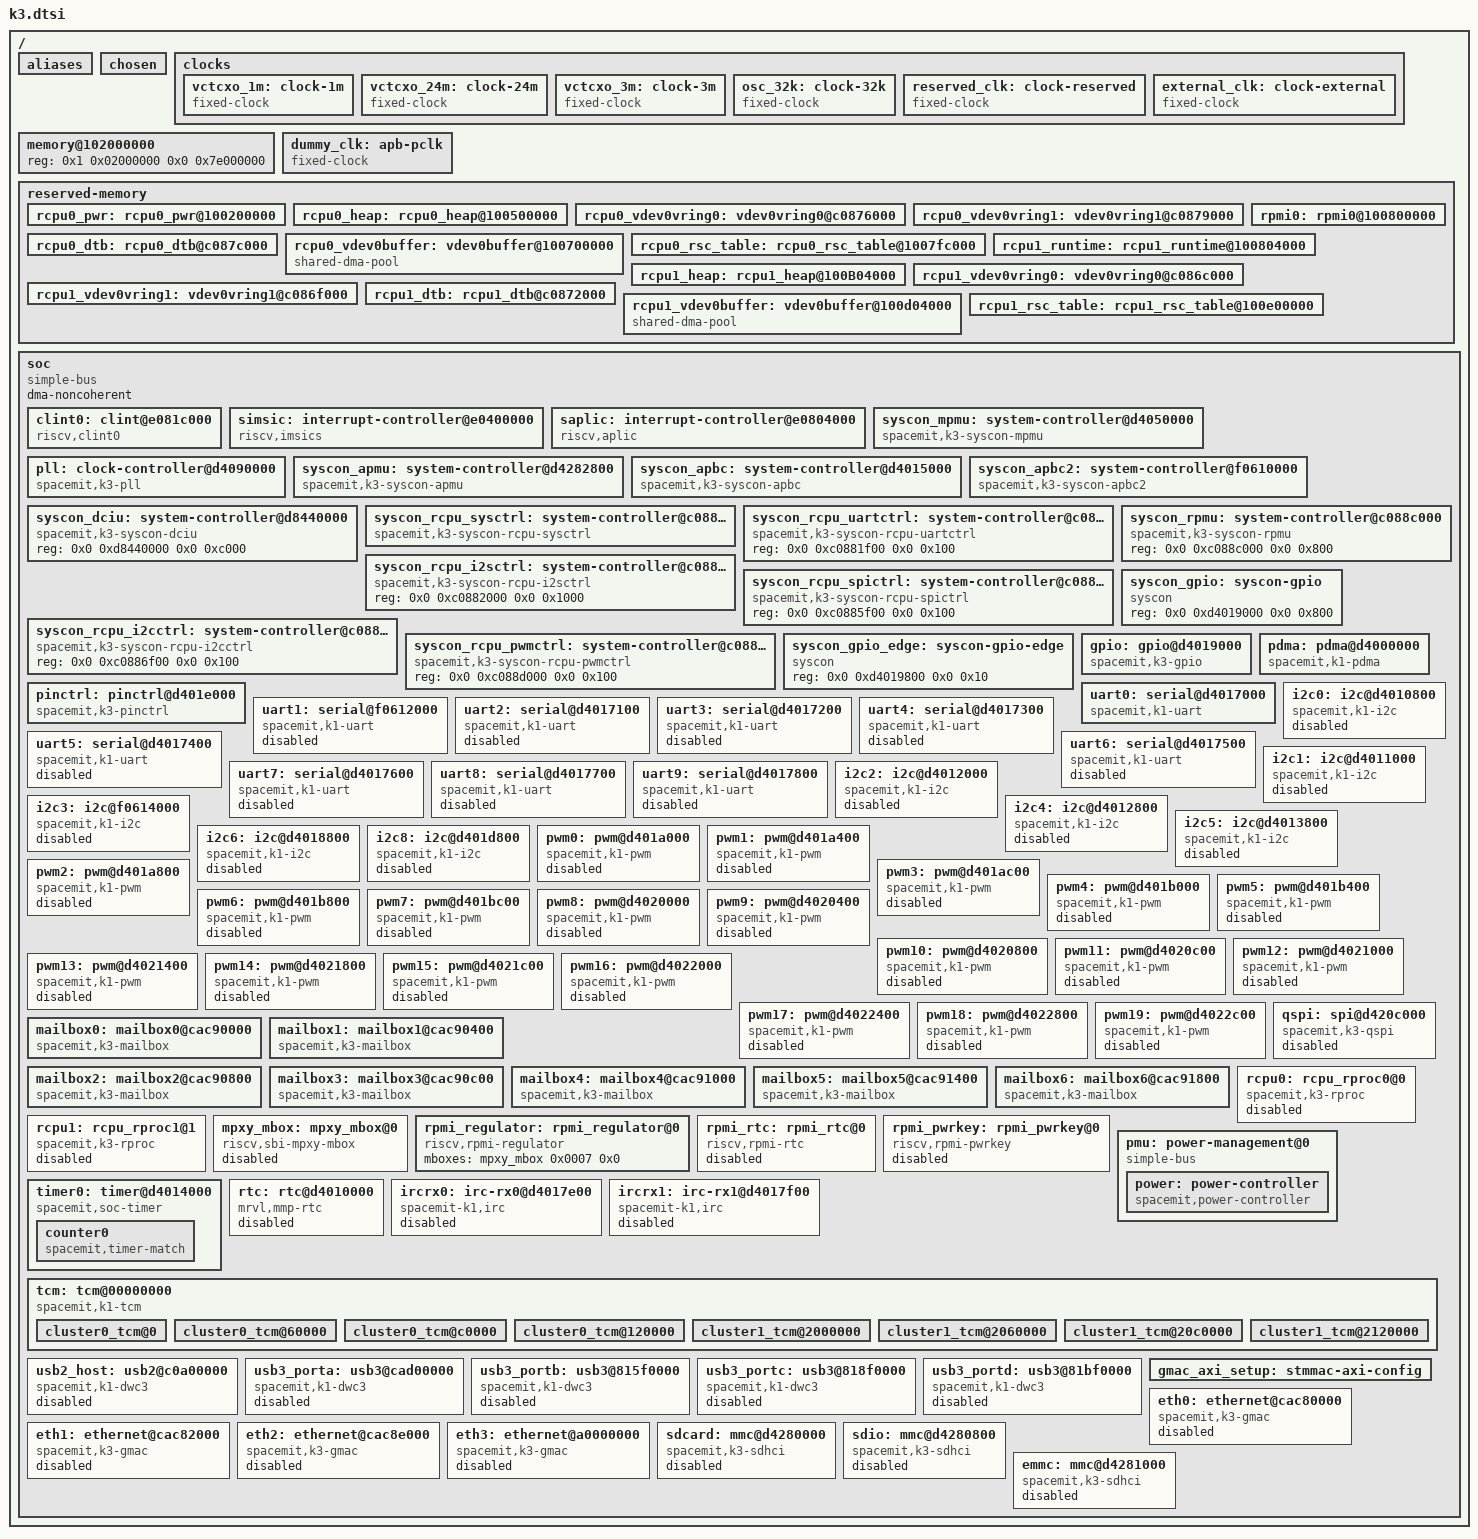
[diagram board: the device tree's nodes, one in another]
// SPDX-License-Identifier: (GPL-2.0 OR MIT)
/* Copyright (c) 2025 Spacemit, Inc */

/dts-v1/;

/* Inline SoC GPIO helper: expand a linear GPIO to <bank,offset> */
#define K3_GPIO(x) ((x) / 32) ((x) % 32)
#include "k3-cpus.dtsi"
#include <dt-bindings/gpio/gpio.h>
#include <dt-bindings/clock/spacemit,k3-syscon.h>
#include <dt-bindings/interrupt-controller/irq.h>

/ {
	#address-cells = <2>;
	#size-cells = <2>;

	aliases {
		serial0 = &uart0;
		serial1 = &uart1;
		serial2 = &uart2;
		serial3 = &uart3;
		serial4 = &uart4;
		serial5 = &uart5;
		serial6 = &uart6;
		serial7 = &uart7;
		serial8 = &uart8;
		serial9 = &uart9;
		serial10 = &r_uart0;
		serial11 = &r_uart1;
		serial12 = &r_uart2;
		serial13 = &r_uart3;
		serial14 = &r_uart4;
		serial15 = &r_uart5;
		mmc0 = &sdcard;
		mmc1 = &sdio;
		mmc2 = &emmc;
		ethernet0 = &eth0;
		ethernet1 = &eth1;
		ethernet2 = &eth2;
		ethernet3 = &eth3;
	};

	chosen {
		bootargs = "earlycon=sbi console=ttyS0,115200 clk_ignore_unused nohlt loglevel=8 initcall_debug=1 memblock=debug";
		stdout-path = "serial0:115200";
	};

	clocks {
		vctcxo_1m: clock-1m {
			compatible = "fixed-clock";
			clock-frequency = <1000000>;
			clock-output-names = "vctcxo_1m";
			#clock-cells = <0>;
		};

		vctcxo_24m: clock-24m {
			compatible = "fixed-clock";
			clock-frequency = <24000000>;
			clock-output-names = "vctcxo_24m";
			#clock-cells = <0>;
		};

		vctcxo_3m: clock-3m {
			compatible = "fixed-clock";
			clock-frequency = <3000000>;
			clock-output-names = "vctcxo_3m";
			#clock-cells = <0>;
		};

		osc_32k: clock-32k {
			compatible = "fixed-clock";
			clock-frequency = <32000>;
			clock-output-names = "osc_32k";
			#clock-cells = <0>;
		};

		reserved_clk: clock-reserved {
			compatible = "fixed-clock";
			clock-frequency = <0>;
			clock-output-names = "reserved_clk";
			#clock-cells = <0>;
		};

		external_clk: clock-external {
			compatible = "fixed-clock";
			clock-frequency = <0>;
			clock-output-names = "external_clk";
			#clock-cells = <0>;
		};
	};

	memory@102000000 {
		device_type = "memory";
		reg = <0x1 0x02000000 0x0 0x7e000000>;
	};

	dummy_clk: apb-pclk {
		compatible = "fixed-clock";
		#clock-cells = <0x0>;
		clock-output-names = "clk14mhz";
		clock-frequency = <14000000>;
	};

	reserved-memory {
		#address-cells = <2>;
		#size-cells = <2>;
		ranges;

		/* used for rcpu0 code & data & bss space */
		rcpu0_pwr: rcpu0_pwr@100200000 {
			reg = <0x1 0x200000 0x0 0x300000>;
			no-map;
		};

		/* rcpu0's heap */
		rcpu0_heap: rcpu0_heap@100500000 {
			reg = <0x1 0x500000 0x0 0x200000>;
			no-map;
		};

		/* vring0 */
		rcpu0_vdev0vring0: vdev0vring0@c0876000 {
			reg = <0x0 0xc0876000 0x0 0x3000>;
			no-map;
		};

		/* vring1 */
		rcpu0_vdev0vring1: vdev0vring1@c0879000 {
			reg = <0x0 0xc0879000 0x0 0x3000>;
			no-map;
		};

		/* rcpu0's dtb */
		rcpu0_dtb: rcpu0_dtb@c087c000 {
			reg = <0x0 0xc087c000 0x0 0x4000>;
			no-map;
		};

		/* the rcpu0's share memory buffer */
		rcpu0_vdev0buffer: vdev0buffer@100700000 {
			compatible = "shared-dma-pool";
			reg = <0x1 0x700000 0x0 0xfc000>;
			no-map;
		};

		/* the rcpu0's resource table */
		rcpu0_rsc_table: rcpu0_rsc_table@1007fc000 {
			reg = <0x1 0x7fc000 0x0 0x4000>;
			no-map;
		};

		/* rpmi */
		rpmi0: rpmi0@100800000 {
			reg = <0x1 0x00800000 0x0 0x4000>;
			no-map;
		};

		/*****************rcpu1**********************/
		/* used for rcp1 code & data & bss space */
		rcpu1_runtime: rcpu1_runtime@100804000 {
			reg = <0x1 0x804000 0x0 0x300000>;
			no-map;
		};

		/* rcpu1's heap */
		rcpu1_heap: rcpu1_heap@100B04000 {
			reg = <0x1 0xb04000 0x0 0x200000>;
			no-map;
		};

		/* vring0 */
		rcpu1_vdev0vring0: vdev0vring0@c086c000 {
			reg = <0x0 0xc086c000 0x0 0x3000>;
			no-map;
		};

		/* vring1 */
		rcpu1_vdev0vring1: vdev0vring1@c086f000 {
			reg = <0x0 0xc086f000 0x0 0x3000>;
			no-map;
		};

		/* rcpu1's dtb */
		rcpu1_dtb: rcpu1_dtb@c0872000 {
			reg = <0x0 0xc0872000 0x0 0x4000>;
			no-map;
		};

		/* the rcpu1's share memory buffer */
		rcpu1_vdev0buffer: vdev0buffer@100d04000 {
			compatible = "shared-dma-pool";
			reg = <0x1 0xd04000 0x0 0xfc000>;
			no-map;
		};

		/* the rcpu1's resource table */
		rcpu1_rsc_table: rcpu1_rsc_table@100e00000 {
			reg = <0x1 0xe00000 0x0 0x4000>;
			no-map;
		};
	};

	soc: soc {
		#address-cells = <2>;
		#size-cells = <2>;
		compatible = "simple-bus";
		dma-noncoherent;
		ranges;

		clint0: clint@e081c000 {
			compatible = "riscv,clint0";
			interrupts-extended = <
				&cpu0_intc  3 &cpu0_intc  7
				&cpu1_intc  3 &cpu1_intc  7
				&cpu2_intc  3 &cpu2_intc  7
				&cpu3_intc  3 &cpu3_intc  7
				&cpu4_intc  3 &cpu4_intc  7
				&cpu5_intc  3 &cpu5_intc  7
				&cpu6_intc  3 &cpu6_intc  7
				&cpu7_intc  3 &cpu7_intc  7
				&cpu8_intc  3 &cpu8_intc  7
				&cpu9_intc  3 &cpu9_intc  7
				&cpu10_intc  3 &cpu10_intc  7
				&cpu11_intc  3 &cpu11_intc  7
				&cpu12_intc  3 &cpu12_intc  7
				&cpu13_intc  3 &cpu13_intc  7
				&cpu14_intc  3 &cpu14_intc  7
				&cpu15_intc  3 &cpu15_intc  7
			>;
			reg = <0x0 0xe081c000 0x0 0x0004000>;
			clint,has-no-64bit-mmio;
		};

		simsic: interrupt-controller@e0400000 {
			compatible = "riscv,imsics";
			interrupts-extended = <
				&cpu0_intc 9 &cpu1_intc 9
				&cpu2_intc 9 &cpu3_intc 9
				&cpu4_intc 9 &cpu5_intc 9
				&cpu6_intc 9 &cpu7_intc 9
				&cpu8_intc 9 &cpu9_intc 9
				&cpu10_intc 9 &cpu11_intc 9
				&cpu12_intc 9 &cpu13_intc 9
				&cpu14_intc 9 &cpu15_intc 9>;

			reg = <0x0 0xe0400000 0x0 0x40000
				0x0 0xe0440000 0x0 0x40000
				0x0 0xe0480000 0x0 0x40000
				0x0 0xe04c0000 0x0 0x40000
				0x0 0xe0500000 0x0 0x40000
				0x0 0xe0540000 0x0 0x40000
				0x0 0xe0580000 0x0 0x40000
				0x0 0xe05c0000 0x0 0x40000
				0x0 0xe0600000 0x0 0x40000
				0x0 0xe0640000 0x0 0x40000
				0x0 0xe0680000 0x0 0x40000
				0x0 0xe06c0000 0x0 0x40000
				0x0 0xe0700000 0x0 0x40000
				0x0 0xe0740000 0x0 0x40000
				0x0 0xe0780000 0x0 0x40000
				0x0 0xe07c0000 0x0 0x40000>;
			interrupt-controller;
			#interrupt-cells = <0>;
			#msi-cells = <0>;
			msi-controller;
			/* Number of interrupt identities: 511 */
			riscv,num-ids = <511>;
			/* Number of guest interrupt identities: 511 */
			riscv,num-guest-ids = <511>;
			/* Number of HART index bits: 4 (2^4 = 16 harts) */
			riscv,hart-index-bits = <4>;
			/*
			 * Number of guest index bits: 6
			 *    2^6 = 64 interrupt files
			 *        = 1 s-level interrupt file + 63 vs-level interrupt files
			 *
			 * But on K3,
			 *   X100: only 7 of the 63 vs-level interrupt files are valid.
			 *   A100: no valid vs-level interrupt files.
			 */
			riscv,guest-index-bits = <6>;
			status = "okay";
		};

		saplic: interrupt-controller@e0804000 {
			compatible = "riscv,aplic";
			/* aplic config */
			reg = <0x0 0xe0804000 0x0 0x4000>;
			msi-parent = <&simsic>;
			#interrupt-cells = <2>;
			interrupt-controller;
			/* the number of wired interrupt sources:512 */
			riscv,num-sources = <512>;
			status = "okay";
		};

		syscon_mpmu: system-controller@d4050000 {
			compatible = "spacemit,k3-syscon-mpmu", "syscon";
			reg = <0x0 0xd4050000 0x0 0x10000>;
			clocks = <&osc_32k>, <&vctcxo_1m>, <&vctcxo_3m>,
				 <&vctcxo_24m>, <&reserved_clk>, <&external_clk>;
			clock-names = "osc_32k", "vctcxo_1m", "vctcxo_3m", "vctcxo_24m",
				      "reserved_clk", "external_clk";
			#clock-cells = <1>;
			#reset-cells = <1>;
		};

		pll: clock-controller@d4090000 {
			compatible = "spacemit,k3-pll";
			reg = <0x0 0xd4090000 0x0 0x10000>;
			clocks = <&vctcxo_24m>;
			spacemit,mpmu = <&syscon_mpmu>;
			#clock-cells = <1>;
		};

		syscon_apmu: system-controller@d4282800 {
			compatible = "spacemit,k3-syscon-apmu", "syscon";
			reg = <0x0 0xd4282800 0x0 0x400>;
			clocks = <&osc_32k>, <&vctcxo_1m>, <&vctcxo_3m>, <&vctcxo_24m>,
				 <&reserved_clk>, <&external_clk>;
			clock-names = "osc_32k", "vctcxo_1m", "vctcxo_3m", "vctcxo_24m",
				      "reserved_clk", "external_clk";
			#clock-cells = <1>;
			#power-domain-cells = <1>;
			#reset-cells = <1>;
		};

		syscon_apbc: system-controller@d4015000 {
			compatible = "spacemit,k3-syscon-apbc";
			reg = <0x0 0xd4015000 0x0 0x1000>;
			clocks = <&osc_32k>, <&vctcxo_1m>, <&vctcxo_3m>, <&vctcxo_24m>,
				 <&reserved_clk>, <&external_clk>;
			clock-names = "osc_32k", "vctcxo_1m", "vctcxo_3m", "vctcxo_24m",
				      "reserved_clk", "external_clk";
			#clock-cells = <1>;
			#reset-cells = <1>;
		};

		syscon_apbc2: system-controller@f0610000 {
			compatible = "spacemit,k3-syscon-apbc2";
			reg = <0x0 0xf0610000 0x0 0x2000>;
			clocks = <&osc_32k>, <&vctcxo_1m>, <&vctcxo_3m>, <&vctcxo_24m>,
				 <&reserved_clk>, <&external_clk>;
			clock-names = "osc_32k", "vctcxo_1m", "vctcxo_3m", "vctcxo_24m",
				      "reserved_clk", "external_clk";
			#clock-cells = <1>;
			#reset-cells = <1>;
		};

		syscon_dciu: system-controller@d8440000 {
			compatible = "spacemit,k3-syscon-dciu";
			reg = <0x0 0xd8440000 0x0 0xc000>;
			#clock-cells = <1>;
			#reset-cells = <1>;
		};

		syscon_rcpu_sysctrl: system-controller@c0880000 {
			compatible = "spacemit,k3-syscon-rcpu-sysctrl", "syscon";
			reg = <0x0 0xc0880000 0x0 0x1000>;
			clocks = <&vctcxo_24m>, <&external_clk>;
			clock-names = "vctcxo_24m", "external_clk";
			#clock-cells = <1>;
			#reset-cells = <1>;
		};

		syscon_rcpu_uartctrl: system-controller@c0881f00 {
			compatible = "spacemit,k3-syscon-rcpu-uartctrl";
			reg = <0x0 0xc0881f00 0x0 0x100>;
			#clock-cells = <1>;
			#reset-cells = <1>;
		};

		syscon_rcpu_i2sctrl: system-controller@c0882000 {
			compatible = "spacemit,k3-syscon-rcpu-i2sctrl";
			reg = <0x0 0xc0882000 0x0 0x1000>;
			#clock-cells = <1>;
			#reset-cells = <1>;
		};

		syscon_rcpu_spictrl: system-controller@c0885f00 {
			compatible = "spacemit,k3-syscon-rcpu-spictrl";
			reg = <0x0 0xc0885f00 0x0 0x100>;
			#clock-cells = <1>;
			#reset-cells = <1>;
		};

		syscon_rcpu_i2cctrl: system-controller@c0886f00 {
			compatible = "spacemit,k3-syscon-rcpu-i2cctrl";
			reg = <0x0 0xc0886f00 0x0 0x100>;
			#clock-cells = <1>;
			#reset-cells = <1>;
		};

		syscon_rpmu: system-controller@c088c000 {
			compatible = "spacemit,k3-syscon-rpmu", "syscon";
			reg = <0x0 0xc088c000 0x0 0x800>;
			#clock-cells = <1>;
			#reset-cells = <1>;
		};

		syscon_rcpu_pwmctrl: system-controller@c088d000 {
			compatible = "spacemit,k3-syscon-rcpu-pwmctrl";
			reg = <0x0 0xc088d000 0x0 0x100>;
			#clock-cells = <1>;
			#reset-cells = <1>;
		};

		syscon_gpio: syscon-gpio{
			compatible = "syscon";
			reg = <0x0 0xd4019000 0x0 0x800>;
		};

		syscon_gpio_edge: syscon-gpio-edge{
			compatible = "syscon";
			reg = <0x0 0xd4019800 0x0 0x10>;
		};

		gpio: gpio@d4019000 {
			compatible = "spacemit,k3-gpio";
			reg = <0x0 0xd4019000 0x0 0x100>;
			clocks = <&syscon_apbc CLK_APBC_GPIO>,
				 <&syscon_apbc CLK_APBC_GPIO_BUS>;
			clock-names = "core", "bus";
			gpio-controller;
			#gpio-cells = <3>;
			interrupts = <58 IRQ_TYPE_LEVEL_HIGH>;
			interrupt-parent = <&saplic>;
			interrupt-controller;
			#interrupt-cells = <3>;
			syscon = <&syscon_gpio>;
			syscon-edge = <&syscon_gpio_edge>;
		};

		pinctrl: pinctrl@d401e000 {
			compatible = "spacemit,k3-pinctrl";
			reg = <0x0 0xd401e000 0x0 0x400>;
			syscon = <&syscon_gpio>;
			syscon-edge = <&syscon_gpio_edge>;
		};

		pdma: pdma@d4000000 {
			compatible = "spacemit,k1-pdma";
			reg = <0x0 0xd4000000 0x0 0x4000>;
			interrupt-parent = <&saplic>;
			interrupts = <72 IRQ_TYPE_LEVEL_HIGH>;
			#dma-cells= <1>;
			#dma-channels = <16>;
			max-burst-size = <64>;
			status = "ok";
		};

		uart0: serial@d4017000 {
			compatible = "spacemit,k1-uart",
				     "intel,xscale-uart";
			reg = <0x0 0xd4017000 0x0 0x100>;
			clocks = <&syscon_apbc CLK_APBC_UART0>,<&syscon_apbc CLK_APBC_UART0_BUS>;
			clock-names = "core", "bus";
			resets = <&syscon_apbc RESET_APBC_UART0>;
			reg-shift = <2>;
			reg-io-width = <4>;
			fifo-size = <256>;
			interrupt-parent = <&saplic>;
			interrupts = <42 IRQ_TYPE_LEVEL_HIGH>;
			status = "ok";
		};

		uart1: serial@f0612000 {
			compatible = "spacemit,k1-uart",
				     "intel,xscale-uart";
			reg = <0x0 0xf0612000 0x0 0x100>;
			clocks = <&syscon_apbc2 CLK_APBC2_SEC_UART1>,
				 <&syscon_apbc2 CLK_APBC2_SEC_UART1_BUS>;
			clock-names = "core", "bus";
			resets = <&syscon_apbc2 RESET_APBC2_SEC_UART1>;
			reg-shift = <2>;
			reg-io-width = <4>;
			fifo-size = <256>;
			interrupt-parent = <&saplic>;
			interrupts = <43 IRQ_TYPE_LEVEL_HIGH>;
			status = "disabled";
		};

		uart2: serial@d4017100 {
			compatible = "spacemit,k1-uart",
				     "intel,xscale-uart";
			reg = <0x0 0xd4017100 0x0 0x100>;
			clocks = <&syscon_apbc CLK_APBC_UART2>,<&syscon_apbc CLK_APBC_UART2_BUS>;
			clock-names = "core", "bus";
			resets = <&syscon_apbc RESET_APBC_UART2>;
			reg-shift = <2>;
			reg-io-width = <4>;
			fifo-size = <256>;
			interrupt-parent = <&saplic>;
			interrupts = <44 IRQ_TYPE_LEVEL_HIGH>;
			status = "disabled";
		};

		uart3: serial@d4017200 {
			compatible = "spacemit,k1-uart",
				     "intel,xscale-uart";
			reg = <0x0 0xd4017200 0x0 0x100>;
			clocks = <&syscon_apbc CLK_APBC_UART3>,<&syscon_apbc CLK_APBC_UART3_BUS>;
			clock-names = "core", "bus";
			resets = <&syscon_apbc RESET_APBC_UART3>;
			reg-shift = <2>;
			reg-io-width = <4>;
			fifo-size = <256>;
			interrupt-parent = <&saplic>;
			interrupts = <45 IRQ_TYPE_LEVEL_HIGH>;
			status = "disabled";
		};

		uart4: serial@d4017300 {
			compatible = "spacemit,k1-uart",
				     "intel,xscale-uart";
			reg = <0x0 0xd4017300 0x0 0x100>;
			clocks = <&syscon_apbc CLK_APBC_UART4>,<&syscon_apbc CLK_APBC_UART4_BUS>;
			clock-names = "core", "bus";
			resets = <&syscon_apbc RESET_APBC_UART4>;
			reg-shift = <2>;
			reg-io-width = <4>;
			fifo-size = <256>;
			interrupt-parent = <&saplic>;
			interrupts = <46 IRQ_TYPE_LEVEL_HIGH>;
			status = "disabled";
		};

		uart5: serial@d4017400 {
			compatible = "spacemit,k1-uart",
				     "intel,xscale-uart";
			reg = <0x0 0xd4017400 0x0 0x100>;
			clocks = <&syscon_apbc CLK_APBC_UART5>,<&syscon_apbc CLK_APBC_UART5_BUS>;
			clock-names = "core", "bus";
			resets = <&syscon_apbc RESET_APBC_UART5>;
			reg-shift = <2>;
			reg-io-width = <4>;
			fifo-size = <256>;
			interrupt-parent = <&saplic>;
			interrupts = <47 IRQ_TYPE_LEVEL_HIGH>;
			status = "disabled";
		};

		uart6: serial@d4017500 {
			compatible = "spacemit,k1-uart",
				     "intel,xscale-uart";
			reg = <0x0 0xd4017500 0x0 0x100>;
			clocks = <&syscon_apbc CLK_APBC_UART6>,<&syscon_apbc CLK_APBC_UART6_BUS>;
			clock-names = "core", "bus";
			resets = <&syscon_apbc RESET_APBC_UART6>;
			reg-shift = <2>;
			reg-io-width = <4>;
			fifo-size = <256>;
			interrupt-parent = <&saplic>;
			interrupts = <48 IRQ_TYPE_LEVEL_HIGH>;
			status = "disabled";
		};

		uart7: serial@d4017600 {
			compatible = "spacemit,k1-uart",
				     "intel,xscale-uart";
			reg = <0x0 0xd4017600 0x0 0x100>;
			clocks = <&syscon_apbc CLK_APBC_UART7>,<&syscon_apbc CLK_APBC_UART7_BUS>;
			clock-names = "core", "bus";
			resets = <&syscon_apbc RESET_APBC_UART7>;
			reg-shift = <2>;
			reg-io-width = <4>;
			fifo-size = <256>;
			interrupt-parent = <&saplic>;
			interrupts = <49 IRQ_TYPE_LEVEL_HIGH>;
			status = "disabled";
		};

		uart8: serial@d4017700 {
			compatible = "spacemit,k1-uart",
				     "intel,xscale-uart";
			reg = <0x0 0xd4017700 0x0 0x100>;
			clocks = <&syscon_apbc CLK_APBC_UART8>,<&syscon_apbc CLK_APBC_UART8_BUS>;
			clock-names = "core", "bus";
			resets = <&syscon_apbc RESET_APBC_UART8>;
			reg-shift = <2>;
			reg-io-width = <4>;
			fifo-size = <256>;
			interrupt-parent = <&saplic>;
			interrupts = <50 IRQ_TYPE_LEVEL_HIGH>;
			status = "disabled";
		};

		uart9: serial@d4017800 {
			compatible = "spacemit,k1-uart",
				     "intel,xscale-uart";
			reg = <0x0 0xd4017800 0x0 0x100>;
			clocks = <&syscon_apbc CLK_APBC_UART9>,<&syscon_apbc CLK_APBC_UART9_BUS>;
			clock-names = "core", "bus";
			resets = <&syscon_apbc RESET_APBC_UART9>;
			reg-shift = <2>;
			reg-io-width = <4>;
			fifo-size = <256>;
			interrupt-parent = <&saplic>;
			interrupts = <51 IRQ_TYPE_LEVEL_HIGH>;
			status = "disabled";
		};

		i2c0: i2c@d4010800 {
			compatible = "spacemit,k1-i2c";
			reg = <0x0 0xd4010800 0x0 0x38>;
			#address-cells = <1>;
			#size-cells = <0>;
			interrupt-parent = <&saplic>;
			interrupts = <36 IRQ_TYPE_LEVEL_HIGH>;
			clocks = <&syscon_apbc CLK_APBC_TWSI0>,
				 <&syscon_apbc CLK_APBC_TWSI0_BUS>;
			clock-names = "func", "bus";
			clock-frequency = <400000>;
			resets = <&syscon_apbc RESET_APBC_TWSI0>;
			status = "disabled";
		};

		i2c1: i2c@d4011000 {
			compatible = "spacemit,k1-i2c";
			reg = <0x0 0xd4011000 0x0 0x38>;
			#address-cells = <1>;
			#size-cells = <0>;
			interrupt-parent = <&saplic>;
			interrupts = <37 IRQ_TYPE_LEVEL_HIGH>;
			clocks = <&syscon_apbc CLK_APBC_TWSI1>,
				 <&syscon_apbc CLK_APBC_TWSI1_BUS>;
			clock-names = "func", "bus";
			clock-frequency = <400000>;
			resets = <&syscon_apbc RESET_APBC_TWSI1>;
			status = "disabled";
		};

		i2c2: i2c@d4012000 {
			compatible = "spacemit,k1-i2c";
			reg = <0x0 0xd4012000 0x0 0x38>;
			#address-cells = <1>;
			#size-cells = <0>;
			interrupt-parent = <&saplic>;
			interrupts = <38 IRQ_TYPE_LEVEL_HIGH>;
			clocks = <&syscon_apbc CLK_APBC_TWSI2>,
				 <&syscon_apbc CLK_APBC_TWSI2_BUS>;
			clock-names = "func", "bus";
			clock-frequency = <400000>;
			resets = <&syscon_apbc RESET_APBC_TWSI2>;
			status = "disabled";
		};

		i2c3: i2c@f0614000 {
			compatible = "spacemit,k1-i2c";
			reg = <0x0 0xf0614000 0x0 0x38>;
			#address-cells = <1>;
			#size-cells = <0>;
			interrupt-parent = <&saplic>;
			interrupts = <39 IRQ_TYPE_LEVEL_HIGH>;
			clocks = <&syscon_apbc2 CLK_APBC2_SEC_TWSI3>,
				 <&syscon_apbc2 CLK_APBC2_SEC_TWSI3_BUS>;
			clock-names = "func", "bus";
			clock-frequency = <400000>;
			resets = <&syscon_apbc2 RESET_APBC2_SEC_TWSI3>;
			status = "disabled";
		};

		i2c4: i2c@d4012800 {
			compatible = "spacemit,k1-i2c";
			reg = <0x0 0xd4012800 0x0 0x38>;
			#address-cells = <1>;
			#size-cells = <0>;
			interrupt-parent = <&saplic>;
			interrupts = <40 IRQ_TYPE_LEVEL_HIGH>;
			clocks = <&syscon_apbc CLK_APBC_TWSI4>,
				 <&syscon_apbc CLK_APBC_TWSI4_BUS>;
			clock-names = "func", "bus";
			clock-frequency = <400000>;
			resets = <&syscon_apbc RESET_APBC_TWSI4>;
			status = "disabled";
		};

		i2c5: i2c@d4013800 {
			compatible = "spacemit,k1-i2c";
			reg = <0x0 0xd4013800 0x0 0x38>;
			#address-cells = <1>;
			#size-cells = <0>;
			interrupt-parent = <&saplic>;
			interrupts = <41 IRQ_TYPE_LEVEL_HIGH>;
			clocks = <&syscon_apbc CLK_APBC_TWSI5>,
				 <&syscon_apbc CLK_APBC_TWSI5_BUS>;
			clock-names = "func", "bus";
			clock-frequency = <400000>;
			resets = <&syscon_apbc RESET_APBC_TWSI5>;
			status = "disabled";
		};

		i2c6: i2c@d4018800 {
			compatible = "spacemit,k1-i2c";
			reg = <0x0 0xd4018800 0x0 0x38>;
			#address-cells = <1>;
			#size-cells = <0>;
			interrupt-parent = <&saplic>;
			interrupts = <70 IRQ_TYPE_LEVEL_HIGH>;
			clocks = <&syscon_apbc CLK_APBC_TWSI6>,
				 <&syscon_apbc CLK_APBC_TWSI6_BUS>;
			clock-names = "func", "bus";
			clock-frequency = <400000>;
			resets = <&syscon_apbc RESET_APBC_TWSI6>;
			status = "disabled";
		};

		i2c8: i2c@d401d800 {
			compatible = "spacemit,k1-i2c";
			reg = <0x0 0xd401d800 0x0 0x38>;
			#address-cells = <1>;
			#size-cells = <0>;
			interrupt-parent = <&saplic>;
			interrupts = <19 IRQ_TYPE_LEVEL_HIGH>;
			clocks = <&syscon_apbc CLK_APBC_TWSI8>,
				 <&syscon_apbc CLK_APBC_TWSI8_BUS>;
			clock-names = "func", "bus";
			clock-frequency = <400000>;
			resets = <&syscon_apbc RESET_APBC_TWSI8>;
			status = "disabled";
		};

		pwm0: pwm@d401a000 {
			compatible = "spacemit,k1-pwm", "marvell,pxa910-pwm";
			reg = <0x0 0xd401a000 0x0 0x10>;
			clocks = <&syscon_apbc CLK_APBC_PWM0>,<&syscon_apbc CLK_APBC_PWM0_BUS>;
			clock-names = "func", "bus";
			resets = <&syscon_apbc RESET_APBC_PWM0>;
			#pwm-cells = <3>;
			k1,pwm-disable-fd;
			status = "disabled";
		};

		pwm1: pwm@d401a400 {
			compatible = "spacemit,k1-pwm", "marvell,pxa910-pwm";
			reg = <0x0 0xd401a400 0x0 0x10>;
			clocks = <&syscon_apbc CLK_APBC_PWM1>,<&syscon_apbc CLK_APBC_PWM1_BUS>;
			clock-names = "func", "bus";
			resets = <&syscon_apbc RESET_APBC_PWM1>;
			#pwm-cells = <3>;
			k1,pwm-disable-fd;
			status = "disabled";
		};

		pwm2: pwm@d401a800 {
			compatible = "spacemit,k1-pwm", "marvell,pxa910-pwm";
			reg = <0x0 0xd401a800 0x0 0x10>;
			clocks = <&syscon_apbc CLK_APBC_PWM2>,<&syscon_apbc CLK_APBC_PWM2_BUS>;
			clock-names = "func", "bus";
			resets = <&syscon_apbc RESET_APBC_PWM2>;
			#pwm-cells = <3>;
			k1,pwm-disable-fd;
			status = "disabled";
		};

		pwm3: pwm@d401ac00 {
			compatible = "spacemit,k1-pwm", "marvell,pxa910-pwm";
			reg = <0x0 0xd401ac00 0x0 0x10>;
			clocks = <&syscon_apbc CLK_APBC_PWM3>,<&syscon_apbc CLK_APBC_PWM3_BUS>;
			clock-names = "func", "bus";
			resets = <&syscon_apbc RESET_APBC_PWM3>;
			#pwm-cells = <3>;
			k1,pwm-disable-fd;
			status = "disabled";
		};

		pwm4: pwm@d401b000 {
			compatible = "spacemit,k1-pwm", "marvell,pxa910-pwm";
			reg = <0x0 0xd401b000 0x0 0x10>;
			clocks = <&syscon_apbc CLK_APBC_PWM4>,<&syscon_apbc CLK_APBC_PWM4_BUS>;
			clock-names = "func", "bus";
			resets = <&syscon_apbc RESET_APBC_PWM4>;
			#pwm-cells = <3>;
			k1,pwm-disable-fd;
			status = "disabled";
		};

		pwm5: pwm@d401b400 {
			compatible = "spacemit,k1-pwm", "marvell,pxa910-pwm";
			reg = <0x0 0xd401b400 0x0 0x10>;
			clocks = <&syscon_apbc CLK_APBC_PWM5>,<&syscon_apbc CLK_APBC_PWM5_BUS>;
			clock-names = "func", "bus";
			resets = <&syscon_apbc RESET_APBC_PWM5>;
			#pwm-cells = <3>;
			k1,pwm-disable-fd;
			status = "disabled";
		};

		pwm6: pwm@d401b800 {
			compatible = "spacemit,k1-pwm", "marvell,pxa910-pwm";
			reg = <0x0 0xd401b800 0x0 0x10>;
			clocks = <&syscon_apbc CLK_APBC_PWM6>,<&syscon_apbc CLK_APBC_PWM6_BUS>;
			clock-names = "func", "bus";
			resets = <&syscon_apbc RESET_APBC_PWM6>;
			#pwm-cells = <3>;
			k1,pwm-disable-fd;
			status = "disabled";
		};

		pwm7: pwm@d401bc00 {
			compatible = "spacemit,k1-pwm", "marvell,pxa910-pwm";
			reg = <0x0 0xd401bc00 0x0 0x10>;
			clocks = <&syscon_apbc CLK_APBC_PWM7>,<&syscon_apbc CLK_APBC_PWM7_BUS>;
			clock-names = "func", "bus";
			resets = <&syscon_apbc RESET_APBC_PWM7>;
			#pwm-cells = <3>;
			k1,pwm-disable-fd;
			status = "disabled";
		};

		pwm8: pwm@d4020000 {
			compatible = "spacemit,k1-pwm", "marvell,pxa910-pwm";
			reg = <0x0 0xd4020000 0x0 0x10>;
			clocks = <&syscon_apbc CLK_APBC_PWM8>,<&syscon_apbc CLK_APBC_PWM8_BUS>;
			clock-names = "func", "bus";
			resets = <&syscon_apbc RESET_APBC_PWM8>;
			#pwm-cells = <3>;
			k1,pwm-disable-fd;
			status = "disabled";
		};

		pwm9: pwm@d4020400 {
			compatible = "spacemit,k1-pwm", "marvell,pxa910-pwm";
			reg = <0x0 0xd4020400 0x0 0x10>;
			clocks = <&syscon_apbc CLK_APBC_PWM9>,<&syscon_apbc CLK_APBC_PWM9_BUS>;
			clock-names = "func", "bus";
			resets = <&syscon_apbc RESET_APBC_PWM9>;
			#pwm-cells = <3>;
			k1,pwm-disable-fd;
			status = "disabled";
		};

		pwm10: pwm@d4020800 {
			compatible = "spacemit,k1-pwm", "marvell,pxa910-pwm";
			reg = <0x0 0xd4020800 0x0 0x10>;
			clocks = <&syscon_apbc CLK_APBC_PWM10>,<&syscon_apbc CLK_APBC_PWM10_BUS>;
			clock-names = "func", "bus";
			resets = <&syscon_apbc RESET_APBC_PWM10>;
			#pwm-cells = <3>;
			k1,pwm-disable-fd;
			status = "disabled";
		};

		pwm11: pwm@d4020c00 {
			compatible = "spacemit,k1-pwm", "marvell,pxa910-pwm";
			reg = <0x0 0xd4020c00 0x0 0x10>;
			clocks = <&syscon_apbc CLK_APBC_PWM11>,<&syscon_apbc CLK_APBC_PWM11_BUS>;
			clock-names = "func", "bus";
			resets = <&syscon_apbc RESET_APBC_PWM11>;
			#pwm-cells = <3>;
			k1,pwm-disable-fd;
			status = "disabled";
		};

		pwm12: pwm@d4021000 {
			compatible = "spacemit,k1-pwm", "marvell,pxa910-pwm";
			reg = <0x0 0xd4021000 0x0 0x10>;
			clocks = <&syscon_apbc CLK_APBC_PWM12>,<&syscon_apbc CLK_APBC_PWM12_BUS>;
			clock-names = "func", "bus";
			resets = <&syscon_apbc RESET_APBC_PWM12>;
			#pwm-cells = <3>;
			k1,pwm-disable-fd;
			status = "disabled";
		};

		pwm13: pwm@d4021400 {
			compatible = "spacemit,k1-pwm", "marvell,pxa910-pwm";
			reg = <0x0 0xd4021400 0x0 0x10>;
			clocks = <&syscon_apbc CLK_APBC_PWM13>,<&syscon_apbc CLK_APBC_PWM13_BUS>;
			clock-names = "func", "bus";
			resets = <&syscon_apbc RESET_APBC_PWM13>;
			#pwm-cells = <3>;
			k1,pwm-disable-fd;
			status = "disabled";
		};

		pwm14: pwm@d4021800 {
			compatible = "spacemit,k1-pwm", "marvell,pxa910-pwm";
			reg = <0x0 0xd4021800 0x0 0x10>;
			clocks = <&syscon_apbc CLK_APBC_PWM14>,<&syscon_apbc CLK_APBC_PWM14_BUS>;
			clock-names = "func", "bus";
			resets = <&syscon_apbc RESET_APBC_PWM14>;
			#pwm-cells = <3>;
			k1,pwm-disable-fd;
			status = "disabled";
		};

		pwm15: pwm@d4021c00 {
			compatible = "spacemit,k1-pwm", "marvell,pxa910-pwm";
			reg = <0x0 0xd4021c00 0x0 0x10>;
			clocks = <&syscon_apbc CLK_APBC_PWM15>,<&syscon_apbc CLK_APBC_PWM15_BUS>;
			clock-names = "func", "bus";
			resets = <&syscon_apbc RESET_APBC_PWM15>;
			#pwm-cells = <3>;
			k1,pwm-disable-fd;
			status = "disabled";
		};

		pwm16: pwm@d4022000 {
			compatible = "spacemit,k1-pwm", "marvell,pxa910-pwm";
			reg = <0x0 0xd4022000 0x0 0x10>;
			clocks = <&syscon_apbc CLK_APBC_PWM16>,<&syscon_apbc CLK_APBC_PWM16_BUS>;
			clock-names = "func", "bus";
			resets = <&syscon_apbc RESET_APBC_PWM16>;
			#pwm-cells = <3>;
			k1,pwm-disable-fd;
			status = "disabled";
		};

		pwm17: pwm@d4022400 {
			compatible = "spacemit,k1-pwm", "marvell,pxa910-pwm";
			reg = <0x0 0xd4022400 0x0 0x10>;
			clocks = <&syscon_apbc CLK_APBC_PWM17>,<&syscon_apbc CLK_APBC_PWM17_BUS>;
			clock-names = "func", "bus";
			resets = <&syscon_apbc RESET_APBC_PWM17>;
			#pwm-cells = <3>;
			k1,pwm-disable-fd;
			status = "disabled";
		};

		pwm18: pwm@d4022800 {
			compatible = "spacemit,k1-pwm", "marvell,pxa910-pwm";
			reg = <0x0 0xd4022800 0x0 0x10>;
			clocks = <&syscon_apbc CLK_APBC_PWM18>,<&syscon_apbc CLK_APBC_PWM18_BUS>;
			clock-names = "func", "bus";
			resets = <&syscon_apbc RESET_APBC_PWM18>;
			#pwm-cells = <3>;
			k1,pwm-disable-fd;
			status = "disabled";
		};

		pwm19: pwm@d4022c00 {
			compatible = "spacemit,k1-pwm", "marvell,pxa910-pwm";
			reg = <0x0 0xd4022c00 0x0 0x10>;
			clocks = <&syscon_apbc CLK_APBC_PWM19>,<&syscon_apbc CLK_APBC_PWM19_BUS>;
			clock-names = "func", "bus";
			resets = <&syscon_apbc RESET_APBC_PWM19>;
			#pwm-cells = <3>;
			k1,pwm-disable-fd;
			status = "disabled";
		};

		qspi: spi@d420c000 {
			compatible = "spacemit,k3-qspi";
			#address-cells = <1>;
			#size-cells = <0>;
			reg = <0x0 0xd420c000 0x0 0x1000>,
			      <0x0 0xb8000000 0x0 0xc00000>;
			reg-names = "qspi-base", "qspi-mmap";
			spacemit,qspi-sfa1ad = <0x4000000>;
			spacemit,qspi-sfa2ad = <0x100000>;
			spacemit,qspi-sfb1ad = <0x100000>;
			spacemit,qspi-sfb2ad = <0x100000>;
			spacemit,qspi-pmuap-reg = <0xd4282860>;
			spacemit,qspi-mpmu-acgr-reg = <0xd4051024>;
			spacemit,qspi-ahb-enable = <0>;
			spacemit,qspi-freq = <26500000>;
			spacemit,qspi-id = <4>;
			interrupts = <117 IRQ_TYPE_LEVEL_HIGH>;
			interrupt-parent = <&saplic>;
			spacemit,qspi-tx-dma = <1>;
			spacemit,qspi-rx-dma = <1>;
			dmas = <&pdma 45>;
			dma-names = "tx-dma";
			status = "disabled";
		};

		mailbox0: mailbox0@cac90000 {
			compatible = "spacemit,k3-mailbox";
			reg = <0x0 0xcac90000 0x0 0x400>;
			interrupt-parent = <&saplic>;
			interrupts = <210 IRQ_TYPE_LEVEL_HIGH>;
			#mbox-cells = <1>;
			status = "okay";
		};

		mailbox1: mailbox1@cac90400 {
			compatible = "spacemit,k3-mailbox";
			reg = <0x0 0xcac90400 0x0 0x400>;
			interrupt-parent = <&saplic>;
			interrupts = <212 IRQ_TYPE_LEVEL_HIGH>;
			#mbox-cells = <1>;
			status = "okay";
		};

		mailbox2: mailbox2@cac90800 {
			compatible = "spacemit,k3-mailbox";
			reg = <0x0 0xcac90800 0x0 0x400>;
			interrupt-parent = <&saplic>;
			interrupts = <214 IRQ_TYPE_LEVEL_HIGH>;
			#mbox-cells = <1>;
			status = "okay";
		};

		mailbox3: mailbox3@cac90c00 {
			compatible = "spacemit,k3-mailbox";
			reg = <0x0 0xcac90c00 0x0 0x400>;
			interrupt-parent = <&saplic>;
			interrupts = <216 IRQ_TYPE_LEVEL_HIGH>;
			#mbox-cells = <1>;
			status = "okay";
		};

		mailbox4: mailbox4@cac91000 {
			compatible = "spacemit,k3-mailbox";
			reg = <0x0 0xcac91000 0x0 0x400>;
			interrupt-parent = <&saplic>;
			interrupts = <217 IRQ_TYPE_LEVEL_HIGH>;
			#mbox-cells = <1>;
			status = "okay";
		};

		mailbox5: mailbox5@cac91400 {
			compatible = "spacemit,k3-mailbox";
			reg = <0x0 0xcac91400 0x0 0x400>;
			interrupt-parent = <&saplic>;
			interrupts = <226 IRQ_TYPE_LEVEL_HIGH>;
			#mbox-cells = <1>;
			status = "okay";
		};

		mailbox6: mailbox6@cac91800 {
			compatible = "spacemit,k3-mailbox";
			reg = <0x0 0xcac91800 0x0 0x400>;
			interrupt-parent = <&saplic>;
			interrupts = <227 IRQ_TYPE_LEVEL_HIGH>;
			#mbox-cells = <1>;
			status = "okay";
		};

		rcpu0: rcpu_rproc0@0 {
			compatible = "spacemit,k3-rproc";
			reg =  <0 0 0 0>;
			mboxes = <&mailbox3 1>, <&mailbox3 2>;
			mbox-names = "vq0", "vq1";
			firmware-name = "k3_rcpu0_esos.elf";
			memory-region = <&rcpu0_pwr>, <&rcpu0_heap>, <&rcpu0_vdev0vring0>, <&rcpu0_vdev0buffer>,
					<&rcpu0_vdev0vring1>, <&rcpu0_rsc_table>;
			status = "disabled";
		};

		rcpu1: rcpu_rproc1@1 {
			compatible = "spacemit,k3-rproc";
			reg =  <0 0 0 0>;
			mboxes = <&mailbox4 0>, <&mailbox4 1>;
			mbox-names = "vq0", "vq1";
			firmware-name = "k3_rcpu1_esos.elf";
			memory-region = <&rcpu1_runtime>, <&rcpu1_heap>, <&rcpu1_vdev0vring0>, <&rcpu1_vdev0buffer>,
					<&rcpu1_vdev0vring1>, <&rcpu1_rsc_table>;
			status = "disabled";
		};

		mpxy_mbox: mpxy_mbox@0 {
			compatible = "riscv,sbi-mpxy-mbox";
			#mbox-cells = <2>;
			status = "disabled";
		};

		rpmi_regulator: rpmi_regulator@0 {
			compatible = "riscv,rpmi-regulator";
			mboxes = <&mpxy_mbox 0x0007 0x0>;
			status = "okay";
		};

		rpmi_rtc: rpmi_rtc@0 {
			compatible = "riscv,rpmi-rtc";
			mboxes = <&mpxy_mbox 0xe 0x0>;
			interrupt-parent = <&saplic>;
			interrupts = <64 4>;
			interrupt-names = "rpmi rtc";
			status = "disabled";
		};

		rpmi_pwrkey: rpmi_pwrkey@0 {
			compatible = "riscv,rpmi-pwrkey";
			mboxes = <&mpxy_mbox 0xf 0x0>;
			interrupt-parent = <&saplic>;
			interrupts = <64 4>;
			interrupt-names = "rpmi pwrkey";
			status = "disabled";
		};

		pmu: power-management@0 {
			compatible = "simple-bus";
			#address-cells = <2>;
			#size-cells = <2>;
			ranges;

			power: power-controller {
				compatible = "spacemit,power-controller";
				mboxes = <&mpxy_mbox 0x9 0x0>;
				#power-domain-cells = <1>;
				#address-cells = <1>;
				#size-cells = <0>;
				spacemit,mpmu = <&syscon_mpmu>;
			};
		};

		timer0: timer@d4014000 {
			compatible = "spacemit,soc-timer";
			reg = <0x0 0xd4014000 0x0 0xc8>;
			spacemit,timer-id = <0>;
			spacemit,timer-fastclk-frequency = <3250000>;
			spacemit,timer-apb-frequency = <52000000>;
			spacemit,timer-frequency = <32768>;
			resets = <&syscon_apbc RESET_APBC_TIMERS1>;
			status = "okay";

			counter0 {
				compatible = "spacemit,timer-match";
				interrupts = <23 IRQ_TYPE_LEVEL_HIGH>;
				interrupt-parent = <&saplic>;
				spacemit,timer-broadcast;
				spacemit,timer-counter-id = <0>;
				status = "okay";
			};
		};

		rtc: rtc@d4010000 {
			compatible = "mrvl,mmp-rtc";
			reg = <0x0 0xd4010000 0x0 0x100>;
			interrupt-parent = <&saplic>;
			interrupts = <21 IRQ_TYPE_LEVEL_HIGH>, <22 IRQ_TYPE_LEVEL_HIGH>;
			interrupt-names = "rtc 1Hz", "rtc alarm";
			resets = <&syscon_apbc RESET_APBC_RTC>;
			status = "disabled";
		};

		ircrx0: irc-rx0@d4017e00 {
			compatible = "spacemit-k1,irc";
			reg = <0x0 0xd4017e00 0x0 0x100>;
			interrupts = <20 IRQ_TYPE_LEVEL_HIGH>;
			interrupt-parent = <&saplic>;
			resets = <&syscon_apbc RESET_APBC_IR0>;
			clock-frequency = <102400000>;
			status = "disabled";
		};

		ircrx1: irc-rx1@d4017f00 {
			compatible = "spacemit-k1,irc";
			reg = <0x0 0xd4017f00 0x0 0x100>;
			interrupts = <69 IRQ_TYPE_LEVEL_HIGH>;
			interrupt-parent = <&saplic>;
			resets = <&syscon_apbc RESET_APBC_IR1>;
			clock-frequency = <102400000>;
			status = "disabled";
		};

		tcm: tcm@00000000 {
			compatible = "spacemit,k1-tcm";
			reg = <0x0 0 0x0 0x4000000>;
			#address-cells = <1>;
			#size-cells = <1>;
			ranges = <0x0 0x0 0 0x4000000>;
			no-memory-wc;
			/* the first range 0x00000~0x180000 */
			cluster0_tcm@0 {
				reg = <0x00000 0x60000>;
				cpus = <&cpu_8>, <&cpu_9>;
				pool;
			};
			cluster0_tcm@60000 {
				reg = <0x60000 0x60000>;
				cpus = <&cpu_8>, <&cpu_9>;
				pool;
			};
			cluster0_tcm@c0000 {
				reg = <0xc0000 0x60000>;
				cpus = <&cpu_10>, <&cpu_11>;
				pool;
			};
			cluster0_tcm@120000 {
				reg = <0x120000 0x60000>;
				cpus = <&cpu_10>, <&cpu_11>;
				pool;
			};

			/* the second range 0x2000000~0x2180000 */
			cluster1_tcm@2000000 {
				reg = <0x2000000 0x60000>;
				cpus = <&cpu_12>, <&cpu_13>;
				pool;
			};
			cluster1_tcm@2060000 {
				reg = <0x2060000 0x60000>;
				cpus = <&cpu_12>, <&cpu_13>;
				pool;
			};
			cluster1_tcm@20c0000 {
				reg = <0x20c0000 0x60000>;
				cpus = <&cpu_14>, <&cpu_15>;
				pool;
			};
			cluster1_tcm@2120000 {
				reg = <0x2120000 0x60000>;
				cpus = <&cpu_14>, <&cpu_15>;
				pool;
			};
		};

		usb2_host: usb2@c0a00000 {
			compatible = "spacemit,k1-dwc3";
			reg = <0x0 0xc0a00000 0x0 0x10000>;
			interrupts = <105 IRQ_TYPE_LEVEL_HIGH>;
			interrupt-parent = <&saplic>;
			clocks = <&syscon_apmu CLK_APMU_USB2_BUS>;
			resets = <&syscon_apmu RESET_APMU_USB2>;
			maximum-speed = "high-speed";
			status = "disabled";
		};

		usb3_porta: usb3@cad00000 {
			compatible = "spacemit,k1-dwc3";
			reg = <0x0 0xcad00000 0x0 0x10000>;
			interrupts = <118 IRQ_TYPE_LEVEL_HIGH>;
			interrupt-parent = <&saplic>;
			clocks = <&syscon_apmu CLK_APMU_USB3_PORTA_BUS>;
			resets = <&syscon_apmu RESET_APMU_USB3_PORTA>;
			status = "disabled";
		};

		usb3_portb: usb3@815f0000 {
			compatible = "spacemit,k1-dwc3";
			reg = <0x0 0x815f0000 0x0 0x10000>;
			interrupts = <125 IRQ_TYPE_LEVEL_HIGH>;
			interrupt-parent = <&saplic>;
			clocks = <&syscon_apmu CLK_APMU_USB3_PORTB_BUS>;
			resets = <&syscon_apmu RESET_APMU_USB3_PORTB>;
			status = "disabled";
		};

		usb3_portc: usb3@818f0000 {
			compatible = "spacemit,k1-dwc3";
			reg = <0x0 0x818f0000 0x0 0x10000>;
			interrupts = <148 IRQ_TYPE_LEVEL_HIGH>;
			interrupt-parent = <&saplic>;
			clocks = <&syscon_apmu CLK_APMU_USB3_PORTC_BUS>;
			resets = <&syscon_apmu RESET_APMU_USB3_PORTC>;
			status = "disabled";
		};

		usb3_portd: usb3@81bf0000 {
			compatible = "spacemit,k1-dwc3";
			reg = <0x0 0x81bf0000 0x0 0x10000>;
			interrupts = <149 IRQ_TYPE_LEVEL_HIGH>;
			interrupt-parent = <&saplic>;
			clocks = <&syscon_apmu CLK_APMU_USB3_PORTD_BUS>;
			resets = <&syscon_apmu RESET_APMU_USB3_PORTD>;
			status = "disabled";
		};

		gmac_axi_setup: stmmac-axi-config {
			snps,wr_osr_lmt = <0xf>;
			snps,rd_osr_lmt = <0xf>;
			/* max axi burst len is 256 */
			snps,blen = <256 128 64 32 16 0 0>;
		};

		eth0: ethernet@cac80000 {
			compatible = "spacemit,k3-gmac", "snps,dwmac-5.10a";
			reg = <0x0 0xcac80000 0x0 0x2000>;
			spacemit,apmu = <&syscon_apmu>;
			spacemit,ctrl-offset = <0x3e4>;
			spacemit,dline-offset = <0x3e8>;
			clocks = <&syscon_apmu CLK_APMU_EMAC0_BUS>,
				 <&syscon_apmu CLK_APMU_EMAC0_1588>;
			clock-names = "stmmaceth", "ptp_ref";
			resets = <&syscon_apmu RESET_APMU_EMAC0>;
			reset-names = "stmmaceth";
			interrupt-parent = <&saplic>;
			interrupts = <131 4>, <276 4>;
			interrupt-names = "macirq", "eth_wake_irq";
			mac-address = [00 00 00 00 00 00];
			snps,axi-config = <&gmac_axi_setup>;
			status = "disabled";
		};

		eth1: ethernet@cac82000 {
			compatible = "spacemit,k3-gmac", "snps,dwmac-5.10a";
			reg = <0x0 0xcac82000 0x0 0x2000>;
			spacemit,apmu = <&syscon_apmu>;
			spacemit,ctrl-offset = <0x3ec>;
			spacemit,dline-offset = <0x3f0>;
			clocks = <&syscon_apmu CLK_APMU_EMAC1_BUS>,
				 <&syscon_apmu CLK_APMU_EMAC1_1588>;
			clock-names = "stmmaceth", "ptp_ref";
			resets = <&syscon_apmu RESET_APMU_EMAC1>;
			reset-names = "stmmaceth";
			interrupt-parent = <&saplic>;
			interrupts = <133 4>, <277 4>;
			interrupt-names = "macirq", "eth_wake_irq";
			mac-address = [00 00 00 00 00 00];
			snps,axi-config = <&gmac_axi_setup>;
			status = "disabled";
		};

		eth2: ethernet@cac8e000 {
			compatible = "spacemit,k3-gmac", "snps,dwmac-5.10a";
			reg = <0x0 0xcac8e000 0x0 0x2000>;
			spacemit,apmu = <&syscon_apmu>;
			spacemit,ctrl-offset = <0x248>;
			spacemit,dline-offset = <0x24c>;
			clocks = <&syscon_apmu CLK_APMU_EMAC2_BUS>,
				 <&syscon_apmu CLK_APMU_EMAC2_1588>;
			clock-names = "stmmaceth", "ptp_ref";
			resets = <&syscon_apmu RESET_APMU_EMAC2>;
			reset-names = "stmmaceth";
			interrupt-parent = <&saplic>;
			interrupts = <130 4>, <278 4>;
			interrupt-names = "macirq", "eth_wake_irq";
			mac-address = [00 00 00 00 00 00];
			snps,axi-config = <&gmac_axi_setup>;
			status = "disabled";
		};

		eth3: ethernet@a0000000 {
			compatible = "spacemit,k3-gmac", "snps,dwmac-5.10a";
			reg = <0x0 0xa0000000 0x0 0x2000>;
			spacemit,apmu = <&syscon_rcpu_sysctrl>;
			spacemit,ctrl-offset = <0x0e4>;
			spacemit,dline-offset = <0x0e8>;
			clocks = <&syscon_rcpu_sysctrl CLK_RCPU_SYSCTRL_REMAC_BUS>,
				 <&syscon_rcpu_sysctrl CLK_RCPU_SYSCTRL_REMAC_1588>;
			clock-names = "stmmaceth", "ptp_ref";
			resets = <&syscon_rcpu_sysctrl RESET_RCPU_SYSCTRL_RGMAC>;
			reset-names = "stmmaceth";
			interrupt-parent = <&saplic>;
			interrupts = <237 4>, <236 4>;
			interrupt-names = "macirq", "eth_wake_irq";
			mac-address = [00 00 00 00 00 00];
			snps,axi-config = <&gmac_axi_setup>;
			status = "disabled";
		};

		sdcard: mmc@d4280000 {
			compatible = "spacemit,k3-sdhci";
			reg = <0x0 0xd4280000 0x0 0x200>;
			clocks = <&syscon_apmu CLK_APMU_SDH_AXI>,
				 <&syscon_apmu CLK_APMU_SDH0>,
				 <&syscon_apbc CLK_APBC_AIB_BUS>,
				 <&syscon_apbc CLK_APBC_AIB>;
			clock-names = "core", "io", "aib-bus", "aib";
			interrupt-parent = <&saplic>;
			interrupts = <99 IRQ_TYPE_LEVEL_HIGH>;
			resets = <&syscon_apmu RESET_APMU_SDH_AXI>,
				 <&syscon_apmu RESET_APMU_SDH0>;
			reset-names = "sdh_axi", "sdh0";
			status = "disabled";
		};

		sdio: mmc@d4280800 {
			compatible = "spacemit,k3-sdhci";
			reg = <0x0 0xd4280800 0x0 0x200>;
			clocks = <&syscon_apmu CLK_APMU_SDH_AXI>,
				 <&syscon_apmu CLK_APMU_SDH1>;
			clock-names = "core", "io";
			interrupt-parent = <&saplic>;
			interrupts = <100 IRQ_TYPE_LEVEL_HIGH>;
			resets = <&syscon_apmu RESET_APMU_SDH_AXI>,
				 <&syscon_apmu RESET_APMU_SDH1>;
			reset-names = "sdh_axi", "sdh1";
			status = "disabled";
		};

		emmc: mmc@d4281000 {
			compatible = "spacemit,k3-sdhci";
			reg = <0x0 0xd4281000 0x0 0x200>;
			clocks = <&syscon_apmu CLK_APMU_SDH_AXI>,
				 <&syscon_apmu CLK_APMU_SDH2>;
			clock-names = "core", "io";
			interrupt-parent = <&saplic>;
			interrupts = <101 IRQ_TYPE_LEVEL_HIGH>;
			resets = <&syscon_apmu RESET_APMU_SDH_AXI>,
				 <&syscon_apmu RESET_APMU_SDH2>;
			reset-names = "sdh_axi", "sdh2";
			status = "disabled";
		};
	};
};
